# STM32WL3xx register map
File version: 1.0
Registers are 32-bit, read-write, reset 0x0 unless marked. A register's access mark holds for its fields unless they carry their own. Offsets are from the block's base; [hi:lo] are bit positions.

## USART1 — Universal synchronous asynchronous receiver transmitter (USART)
Base 0x41004000
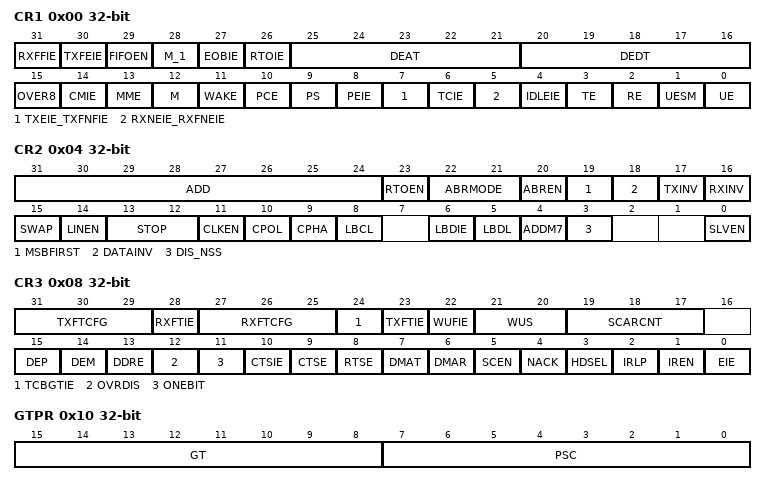
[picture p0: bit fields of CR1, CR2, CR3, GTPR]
0x00 CR1 — (@ 0x00000000) Control register 1
  [31] RXFFIE
  [30] TXFEIE
  [29] FIFOEN
  [28] M_1
  [27] EOBIE
  [26] RTOIE
  [25:21] DEAT
  [20:16] DEDT
  [15] OVER8
    0=OVERSAMPLING_16 (Oversampling by 16); 1=OVERSAMPLING_8 (Oversampling by 8)
  [14] CMIE
  [13] MME
  [12] M
  [11] WAKE
    0=IDLELINE (LPUART wake up from Mute mode on Idle Line); 1=ADDRESSMARK (LPUART wake up from Mute mode on Address Mark)
  [10] PCE
  [9] PS
  [8] PEIE
  [7] TXEIE_TXFNFIE
  [6] TCIE
  [5] RXNEIE_RXFNEIE
  [4] IDLEIE
  [3] TE
  [2] RE
  [1] UESM
  [0] UE
0x04 CR2 — (@ 0x00000004) Control register 2
  [31:24] ADD
  [23] RTOEN
  [22:21] ABRMODE
    0=STARTBIT (Measurement of the start bit is used to detect the baud rate); 1=FALLINGEDGE (Falling edge to falling edge measurement. Received frame must start with a single bit = 1 -> Frame = Start10xxxxxx); 2=ON_7F_FRAME (0x7F frame detection); 3=ON_55_FRAME (0x55 frame detection)
  [20] ABREN
  [19] MSBFIRST
    0=LSBFIRST; 1=MSBFIRST
  [18] DATAINV
    0=POSITIVE; 1=NEGATIVE
  [17] TXINV
    0=STANDARD (TX pin signal works using the standard logic levels); 1=INVERTED (TX pin signal values are inverted.)
  [16] RXINV
    0=STANDARD (RX pin signal works using the standard logic levels); 1=INVERTED (RX pin signal values are inverted.)
  [15] SWAP
    0=STANDARD (TX/RX pins are used as defined in standard pinout); 1=SWAPPED (TX and RX pins functions are swapped.)
  [14] LINEN
  [13:12] STOP
    0=STOPBITS_1 (1 stop bit); 2=STOPBITS_2 (2 stop bits); 1=STOPBITS_0_5 (0.5 stop bit); 3=STOPBITS_1_5 (1.5 stop bits)
  [11] CLKEN
  [10] CPOL
    0=LOW (Steady low value on SCLK pin outside transmission window); 1=HIGH (Steady high value on SCLK pin outside transmission window)
  [9] CPHA
    0=PHASE_1EDGE (The first clock transition is the first data capture edge); 1=PHASE_2EDGE (The second clock transition is the first data capture edge)
  [8] LBCL
    0=NO_OUTPUT (The clock pulse of the last data bit is not output to the SCLK pin); 1=OUTPUT (The clock pulse of the last data bit is output to the SCLK pin)
  [6] LBDIE
  [5] LBDL
    0=DETECT_10B (10-bit break detection method selected); 1=DETECT_11B (11-bit break detection method selected)
  [4] ADDM7
    0=DETECT_4B (4-bit address detection method selected); 1=DETECT_7B (7-bit address detection (in 8-bit data mode) method selected)
  [3] DIS_NSS
  [0] SLVEN
0x08 CR3 — (@ 0x00000008) Control register 3
  [31:29] TXFTCFG
  [28] RXFTIE
  [27:25] RXFTCFG
  [24] TCBGTIE
  [23] TXFTIE
  [22] WUFIE
  [21:20] WUS
    0=ADDRESS (Wake up active on address match); 2=STARTBIT (Wake up active on Start bit detection); 3=RXNE (Wake up active on RXNE)
  [19:17] SCARCNT
  [15] DEP
    0=HIGH (DE signal is active high); 1=LOW (DE signal is active low)
  [14] DEM
  [13] DDRE
  [12] OVRDIS
  [11] ONEBIT
  [10] CTSIE
  [9] CTSE
  [8] RTSE
  [7] DMAT
  [6] DMAR
  [5] SCEN
  [4] NACK
  [3] HDSEL
  [2] IRLP
    0=NORMAL (IrDA normal power mode); 1=LOW (IrDA low power mode)
  [1] IREN
  [0] EIE
0x0C BRR — (@ 0x0000000C) Baud rate register
  [19:0] BRR
0x10 GTPR — (@ 0x00000010) Guard time and prescaler register
  [15:8] GT, [7:0] PSC
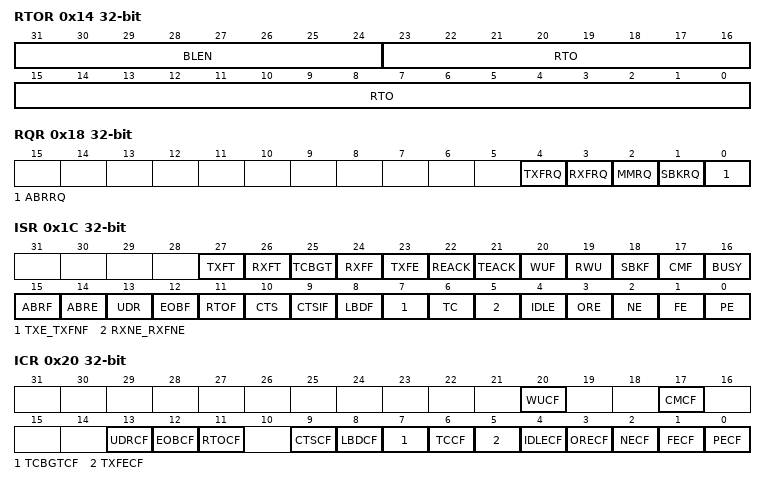
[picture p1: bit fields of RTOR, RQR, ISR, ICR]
0x14 RTOR — (@ 0x00000014) Receiver timeout register
  [31:24] BLEN, [23:0] RTO
0x18 RQR — (@ 0x00000018) Request register
  [4] TXFRQ, [3] RXFRQ, [2] MMRQ, [1] SBKRQ, [0] ABRRQ
0x1C ISR — (@ 0x0000001C) Interrupt & status register
  [27] TXFT, [26] RXFT, [25] TCBGT, [24] RXFF, [23] TXFE, [22] REACK, [21] TEACK, [20] WUF, [19] RWU, [18] SBKF, [17] CMF, [16] BUSY, [15] ABRF, [14] ABRE, [13] UDR, [12] EOBF, [11] RTOF, [10] CTS, [9] CTSIF, [8] LBDF, [7] TXE_TXFNF, [6] TC, [5] RXNE_RXFNE, [4] IDLE, [3] ORE, [2] NE, [1] FE, [0] PE
0x20 ICR — (@ 0x00000020) Interrupt flag clear register
  [20] WUCF, [17] CMCF, [13] UDRCF, [12] EOBCF, [11] RTOCF, [9] CTSCF, [8] LBDCF, [7] TCBGTCF, [6] TCCF, [5] TXFECF, [4] IDLECF, [3] ORECF, [2] NECF, [1] FECF, [0] PECF
0x24 RDR — (@ 0x00000024) Receive data register
  [8:0] RDR
0x28 TDR — (@ 0x00000028) Transmit data register
  [8:0] TDR
0x2C PRESC — (@ 0x0000002C) Prescaler register
  [3:0] PRESCALER
    0=DIV1 (Input clock not divided); 1=DIV2 (Input clock divided by 2); 2=DIV4 (Input clock divided by 4); 3=DIV6; 4=DIV8 (Input clock divided by 8); 5=DIV10; 6=DIV12; 7=DIV16; 8=DIV32 (Input clock divided by 32); 9=DIV64; 10=DIV128; 11=DIV256
